# FM33FK5XX register map
File version: 1.0
CPU: Cortex-M33 r1p0, little endian, MPU, FPU, 3 interrupt priority bits
Registers are 32-bit, read-write, reset 0x0 unless marked. A register's access mark holds for its fields unless they carry their own. Offsets are from the block's base; [hi:lo] are bit positions.

## UART — UART module information
Base 0x40017C00
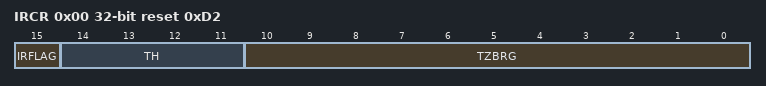
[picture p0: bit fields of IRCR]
0x00 IRCR reset 0xD2 — InfraredmodulationControlRegister
  [15] IRFLAG — IRFLAG field description
  [14:11] TH — TH field description
  [10:0] TZBRG — TZBRG field description

## LPUART0 — LPUART0 module information
Base 0x40020400
Same registers: LPUART1 0x40020800
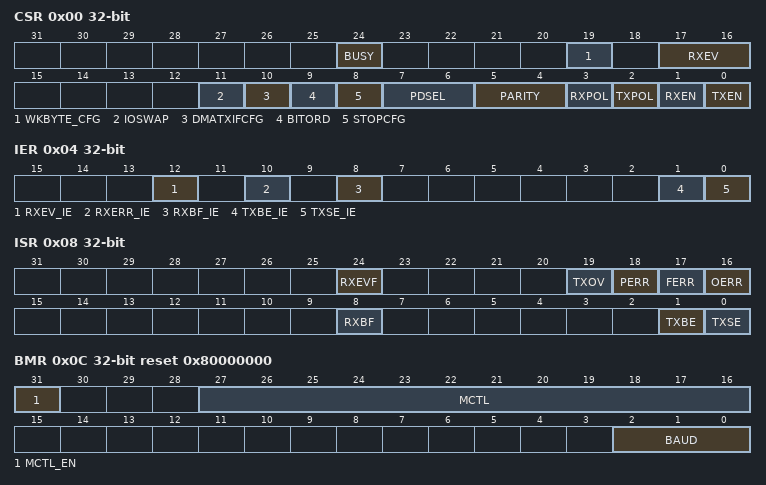
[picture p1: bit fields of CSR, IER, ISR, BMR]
0x00 CSR access per field — LPUART0ControlStatusRegister
  [24] BUSY ro — BUSY field description
  [19] WKBYTE_CFG rw — WKBYTE_CFG field description
  [17:16] RXEV rw — RXEV field description
  [11] IOSWAP rw — IOSWAP field description
  [10] DMATXIFCFG rw — DMATXIFCFG field description
  [9] BITORD rw — BITORD field description
  [8] STOPCFG rw — STOPCFG field description
  [7:6] PDSEL rw — PDSEL field description
  [5:4] PARITY rw — PARITY field description
  [3] RXPOL rw — RXPOL field description
  [2] TXPOL rw — TXPOL field description
  [1] RXEN rw — RXEN field description
  [0] TXEN rw — TXEN field description
0x04 IER — LPUART0InterruptEnableRegister
  [12] RXEV_IE — RXEV_IE field description
  [10] RXERR_IE — RXERR_IE field description
  [8] RXBF_IE — RXBF_IE field description
  [1] TXBE_IE — TXBE_IE field description
  [0] TXSE_IE — TXSE_IE field description
0x08 ISR — LPUART0InterruptStatusRegister
  [24] RXEVF — RXEVF field description
  [19] TXOV — TXOV field description
  [18] PERR — PERR field description
  [17] FERR — FERR field description
  [16] OERR — OERR field description
  [8] RXBF — RXBF field description
  [1] TXBE — TXBE field description
  [0] TXSE — TXSE field description
0x0C BMR reset 0x80000000 — LPUART0BaudrateModulationRegister
  [31] MCTL_EN — MCTL_EN field description
  [27:16] MCTL — MCTL field description
  [2:0] BAUD — BAUD field description
0x10 RXBUF ro — LPUART0ReceiveBufferRegister
  [8:0] RXBUF — RXBUF field description
0x14 TXBUF — LPUART0TransmitBufferRegister
  [8:0] TXBUF — TXBUF field description
0x18 DMR — LPUART0dataMatchingRegister
  [8:0] MATD — MATD field description

## SPI0 — SPI0 module information
Base 0x40019000
Same registers: SPI4 0x40010000, SPI3 0x40010400, SPI2 0x40010800, SPI1 0x40018C00
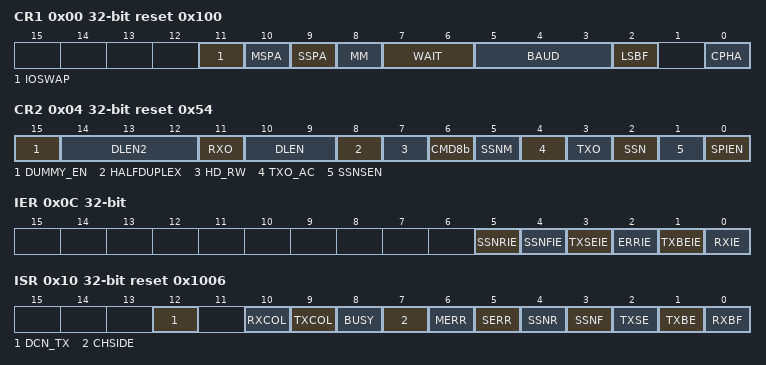
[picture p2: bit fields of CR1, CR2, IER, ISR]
0x00 CR1 reset 0x100 — SPI0ControlRegister1
  [11] IOSWAP — IOSWAP field description
  [10] MSPA — MSPA field description
  [9] SSPA — SSPA field description
  [8] MM — MM field description
  [7:6] WAIT — WAIT field description
  [5:3] BAUD — BAUD field description
  [2] LSBF — LSBF field description
  [0] CPHA — CPHA field description
0x04 CR2 reset 0x54 — SPI0ControlRegister2
  [15] DUMMY_EN — DUMMY_EN field description
  [14:12] DLEN2 — DLEN2 field description
  [11] RXO — RXO field description
  [10:9] DLEN — DLEN field description
  [8] HALFDUPLEX — HALFDUPLEX field description
  [7] HD_RW — HD_RW field description
  [6] CMD8b — CMD8b field description
  [5] SSNM — SSNM field description
  [4] TXO_AC — TXO_AC field description
  [3] TXO — TXO field description
  [2] SSN — SSN field description
  [1] SSNSEN — SSNSEN field description
  [0] SPIEN — SPIEN field description
0x0C IER — SPI0InterruptEnableRegister
  [5] SSNRIE — SSNRIE field description
  [4] SSNFIE — SSNFIE field description
  [3] TXSEIE — TXSEIE field description
  [2] ERRIE — ERRIE field description
  [1] TXBEIE — TXBEIE field description
  [0] RXIE — RXIE field description
0x10 ISR access per field reset 0x1006 — SPI0StatusRegister
  [12] DCN_TX rw — DCN_TX field description
  [10] RXCOL rw — RXCOL field description
  [9] TXCOL rw — TXCOL field description
  [8] BUSY ro — BUSY field description
  [7] CHSIDE ro — CHSIDE field description
  [6] MERR rw — MERR field description
  [5] SERR rw — SERR field description
  [4] SSNR rw — SSNR field description
  [3] SSNF rw — SSNF field description
  [2] TXSE ro — TXSE field description
  [1] TXBE ro — TXBE field description
  [0] RXBF ro — RXBF field description
0x14 TXBUF wo — SPI0TransmitBuffer
  [31:0] TXBUF — TXBUF field description
0x18 RXBUF ro — SPI0ReceiveBuffer
  [31:0] RXBUF — RXBUF field description
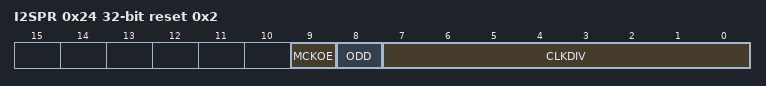
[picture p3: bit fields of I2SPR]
0x24 I2SPR reset 0x2 — SPI0I2SPrescalerRegister
  [9] MCKOE — MCKOE field description
  [8] ODD — ODD field description
  [7:0] CLKDIV — CLKDIV field description
